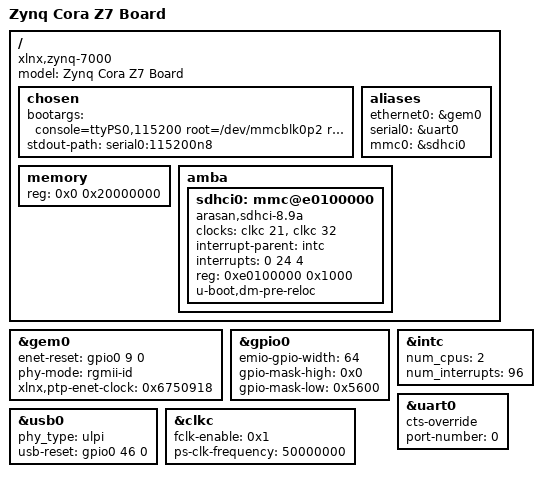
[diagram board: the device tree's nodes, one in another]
/*
 * CAUTION: This file is automatically generated by Xilinx.
 * Version:  
 * Today is: Sun Aug  2 21:23:38 2020
 */

/dts-v1/;
#include "zynq-7000.dtsi"

/delete-node/ &sdhci0;
/ {
	model = "Zynq Cora Z7 Board";
	compatible = "xlnx,zynq-7000";

	chosen {
		bootargs = "console=ttyPS0,115200 root=/dev/mmcblk0p2 rw earlyprintk rootfstype=ext4 rootwait";
		/*bootargs = "earlycon";*/
		stdout-path = "serial0:115200n8";
	};
	aliases {
		ethernet0 = &gem0;
		serial0 = &uart0;
		mmc0 = &sdhci0;
	};
	memory {
		device_type = "memory";
		reg = <0x0 0x20000000>;
	};

    amba: amba {
		sdhci0: mmc@e0100000 {
			compatible = "arasan,sdhci-8.9a";
			status = "disabled";
			clock-names = "clk_xin", "clk_ahb";
			clocks = <&clkc 21>, <&clkc 32>;
			interrupt-parent = <&intc>;
			interrupts = <0 24 4>;
			reg = <0xe0100000 0x1000>;
		};
    };
};

&gem0 {
	enet-reset = <&gpio0 9 0>;
	phy-mode = "rgmii-id";
	status = "okay";
	xlnx,ptp-enet-clock = <0x6750918>;
};

&gpio0 {
	emio-gpio-width = <64>;
	gpio-mask-high = <0x0>;
	gpio-mask-low = <0x5600>;
};

&intc {
	num_cpus = <2>;
	num_interrupts = <96>;
};

&sdhci0 {
	u-boot,dm-pre-reloc;
	status = "okay";
};

&uart0 {
	cts-override ;
	device_type = "serial";
	port-number = <0>;
	status = "okay";
};

&usb0 {
	phy_type = "ulpi";
	status = "okay";
	usb-reset = <&gpio0 46 0>;
};

&clkc {
	fclk-enable = <0x1>;
	ps-clk-frequency = <50000000>;
};
